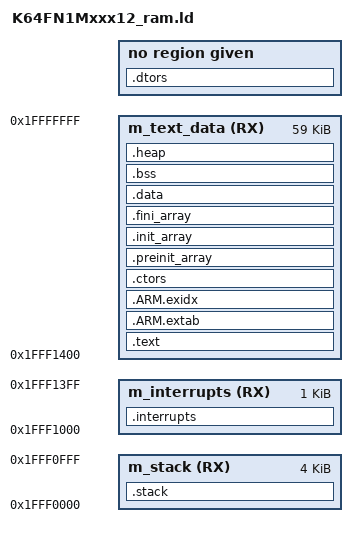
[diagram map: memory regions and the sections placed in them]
/* Linker file for GNU C Compiler */
/* Entry Point */
ENTRY(reset_isr)

HEAP_SIZE  = DEFINED(__heap_size__)  ? __heap_size__  : 0;
STACK_SIZE = DEFINED(__stack_size__) ? __stack_size__ : 0x1000;

/* Specify the memory areas */
MEMORY {
  m_stack         (RX)  : ORIGIN = 0x1FFF0000, LENGTH = 0x00001000
  m_interrupts    (RX)  : ORIGIN = 0x1FFF1000, LENGTH = 0x00000400
  m_text_data     (RX)  : ORIGIN = 0x1FFF1400, LENGTH = 0x0000EC00
}

/* Define output sections */
SECTIONS
{
  .interrupts :
  {
    __VECTOR_TABLE = .;
    . = ALIGN(4);
    KEEP(*(.isr_vector))     /* Startup code */
    . = ALIGN(4);
  } > m_interrupts

  /* The program code and other data goes into INTERNAL_FLASH */
  
  .text :
  {
    . = ALIGN(4);
    *(.text)                 /* .text sections (code) */
    *(.text*)                /* .text* sections (code) */
    *(.rodata)               /* .rodata sections (constants, strings, etc.) */
    *(.rodata*)              /* .rodata* sections (constants, strings, etc.) */
    *(.glue_7)               /* glue arm to thumb code */
    *(.glue_7t)              /* glue thumb to arm code */
    *(.eh_frame)
    KEEP (*(.init))
    KEEP (*(.fini))
    . = ALIGN(4);
  } > m_text_data
  
  .ARM.extab :
  {
     *(.ARM.extab* .gnu.linkonce.armextab.*)
  } > m_text_data

  __exidx_start = .;
  .ARM.exidx :
  {
    *(.ARM.exidx* .gnu.linkonce.armexidx.*)
  } > m_text_data

  __exidx_end = .;

 .ctors :
  {
    __CTOR_LIST__ = .;
    /* gcc uses crtbegin.o to find the start of
       the constructors, so we make sure it is
       first.  Because this is a wildcard, it
       doesn't matter if the user does not
       actually link against crtbegin.o; the
       linker won't look for a file to match a
       wildcard.  The wildcard also means that it
       doesn't matter which directory crtbegin.o
       is in.  */
    KEEP (*crtbegin.o(.ctors))
    KEEP (*crtbegin?.o(.ctors))
    /* We don't want to include the .ctor section from
       from the crtend.o file until after the sorted ctors.
       The .ctor section from the crtend file contains the
       end of ctors marker and it must be last */
    KEEP (*(EXCLUDE_FILE(*crtend?.o *crtend.o) .ctors))
    KEEP (*(SORT(.ctors.*)))
    KEEP (*(.ctors))
    __CTOR_END__ = .;
  } > m_text_data

  .dtors :
  {
    __DTOR_LIST__ = .;
    KEEP (*crtbegin.o(.dtors))
    KEEP (*crtbegin?.o(.dtors))
    KEEP (*(EXCLUDE_FILE(*crtend?.o *crtend.o) .dtors))
    KEEP (*(SORT(.dtors.*)))
    KEEP (*(.dtors))
    __DTOR_END__ = .;
  } > m_text

  .preinit_array :
  {
    PROVIDE_HIDDEN (__preinit_array_start = .);
    KEEP (*(.preinit_array*))
    PROVIDE_HIDDEN (__preinit_array_end = .);
  } > m_text_data
  
  .init_array :
  {
    PROVIDE_HIDDEN (__init_array_start = .);
    KEEP (*(SORT(.init_array.*)))
    KEEP (*(.init_array))
    PROVIDE_HIDDEN (__init_array_end = .);
  } > m_text_data
  
  .fini_array :
  {
    PROVIDE_HIDDEN (__fini_array_start = .);
    KEEP (*(SORT(.fini_array.*)))
    KEEP (*(.fini_array*))
    PROVIDE_HIDDEN (__fini_array_end = .);
  } > m_text_data
  
  .data : 
  {
    . = ALIGN(4);
    __DATA_RAM = .;
    __data_start__ = .;      /* create a global symbol at data start */
    *(.data)                 /* .data sections */
    *(.data*)                /* .data* sections */
    KEEP(*(.jcr*))
    . = ALIGN(4);
    __data_end__ = .;        /* define a global symbol at data end */
  } > m_text_data
  
  /* Uninitialized data section */
  .bss :
  {
    /* This is used by the startup in order to initialize the .bss section */
    . = ALIGN(4);
    __START_BSS = .;
    __bss_start__ = .;
    *(.bss)
    *(.bss*)
    *(COMMON)
    . = ALIGN(4);
    __bss_end__ = .;
    __END_BSS = .;
  } > m_text_data

  .heap :
  {
    . = ALIGN(8);
    __end__ = .;
    PROVIDE(end = .);
    __HeapBase = .;
    . += HEAP_SIZE;
    __HeapLimit = .;
  } > m_text_data
  
  .stack :
  {
    . = ALIGN(8);
    . += STACK_SIZE;
  } > m_stack
  
  __StackTop   = .;
  __StackLimit = __StackTop - STACK_SIZE;
  PROVIDE(__stack = __StackTop);
  
  .ARM.attributes 0 : { *(.ARM.attributes) }
}
